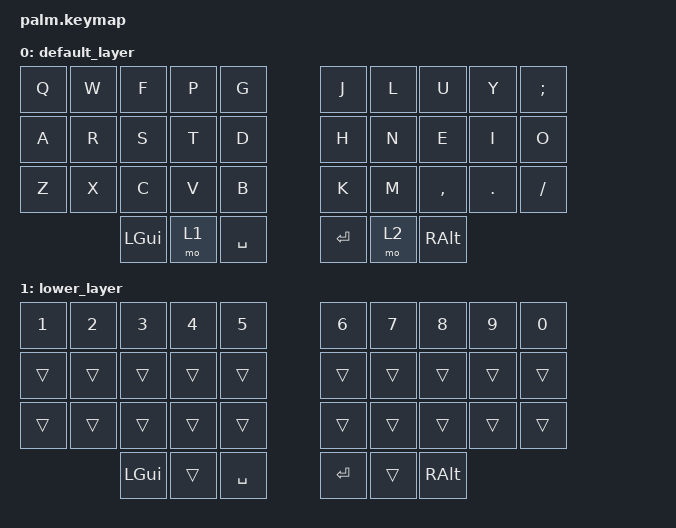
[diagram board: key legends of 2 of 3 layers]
/*
 * Copyright (c) 2020 The ZMK Contributors
 *
 * SPDX-License-Identifier: MIT
 */

#include <behaviors.dtsi>
#include <dt-bindings/zmk/keys.h>
#include <dt-bindings/zmk/bt.h>

/ {
    keymap {
        compatible = "zmk,keymap";

        default_layer {
            // -------------------------------------------------------------------
            // |  Q  |  W  |  F  |  P  |  G  |   |  J  |  L   |  U  |  Y  |  ;  |
            // |  A  |  R  |  S  |  T  |  D  |   |  H  |  N   |  E  |  I  |  O  |
            // |  Z  |  X  |  C  |  V  |  B  |   |  K  |  M   |  ,  |  .  |  /  |
            //             | GUI | LWR | SPC |   | ENT | RSE  | ALT |
            bindings = <
            &kp Q &kp W &kp F &kp P &kp G         &kp J &kp L &kp U     &kp Y   &kp SEMI            //    &kp BSPC
            &kp A &kp R &kp S &kp T &kp D         &kp H &kp N &kp E     &kp I   &kp O            // &kp SQT
            &kp Z &kp X &kp C &kp V &kp B         &kp K &kp M &kp COMMA &kp DOT &kp FSLH  // &kp ESC
                    &kp LGUI &mo 1 &kp SPACE   &kp RET &mo 2 &kp RALT
            >;
        };
        
        lower_layer {
            // ------------------------------------------------------------------
            // |  1  |  2  |  3  |  4  |  5  |   |  6  |  7  |  8  |  9  |  0  |
            // |     |     |     |     |     |   |     | LFT |  UP | RGT |     |
            // |     |     |     |     |     |   |     |     | DWN |     |     |
            //             | GUI |     | SPC |   | ENT |     | ALT |
            bindings = <
            &kp N1  &kp N2  &kp N3  &kp N4  &kp N5         &kp N6  &kp N7  &kp N8  &kp N9  &kp N0
            &trans  &trans  &trans  &trans  &trans         &trans  &trans  &trans  &trans  &trans
            &trans  &trans  &trans  &trans  &trans         &trans  &trans  &trans  &trans  &trans
                         &kp LGUI  &trans  &kp SPACE     &kp RET  &trans   &kp RALT
            >;
        };

        raise_layer {
            // ------------------------------------------------------------------
            // |  !  |  @  |  #  |  $  |  %  |   |  ^  |  &  |  *  |  (  |  )  |
            // |     |     |     |     |     |   |  -  |  =  |  [  |  ]  |  \  |
            // |     |     |     |     |     |   |  _  |  +  |  {  |  }  | "|" |
            //             | GUI |     | SPC |   | ENT |     | ALT |
            bindings = <
            &kp  TAB  &kp EXCL &kp AT &kp HASH &kp DLLR &kp PRCNT   &kp CARET &kp AMPS  &kp ASTRK &kp LPAR &kp RPAR &kp BSPC
            &kp LCTRL &trans   &trans &trans   &trans   &trans      &kp MINUS &kp EQUAL &kp LBKT  &kp RBKT &kp BSLH &kp GRAVE
            &kp LSHFT &trans   &trans &trans   &trans   &trans      &kp UNDER &kp PLUS  &kp LBRC  &kp RBRC &kp PIPE &kp TILDE
                                    &kp LGUI &trans   &kp SPACE   &kp RET   &trans    &kp RALT
            >;
        };
    };
};
